VERSION "1.0"

NS_ :

BS_:

BU_: BatteryECU DigitalTwin

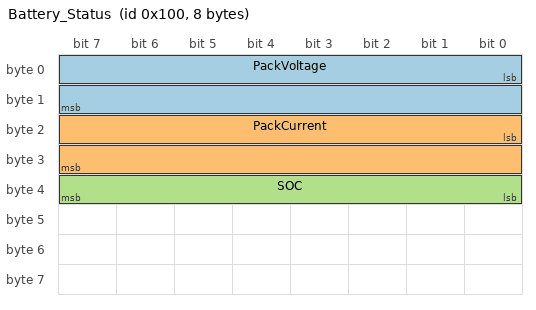
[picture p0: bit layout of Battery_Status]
BO_ 256 Battery_Status: 8 BatteryECU
 SG_ PackVoltage : 0|16@1+ (0.1,0) [0|6553.5] "V" DigitalTwin
 SG_ PackCurrent : 16|16@1- (0.1,0) [-3276.8|3276.7] "A" DigitalTwin
 SG_ SOC : 32|8@1+ (0.5,0) [0|100] "%" DigitalTwin

BO_ 257 Battery_Thermal: 8 BatteryECU
 SG_ PackTemperature : 0|16@1- (0.1,0) [-3276.8|3276.7] "degC" DigitalTwin
 SG_ SOH : 16|8@1+ (0.5,0) [0|100] "%" DigitalTwin
